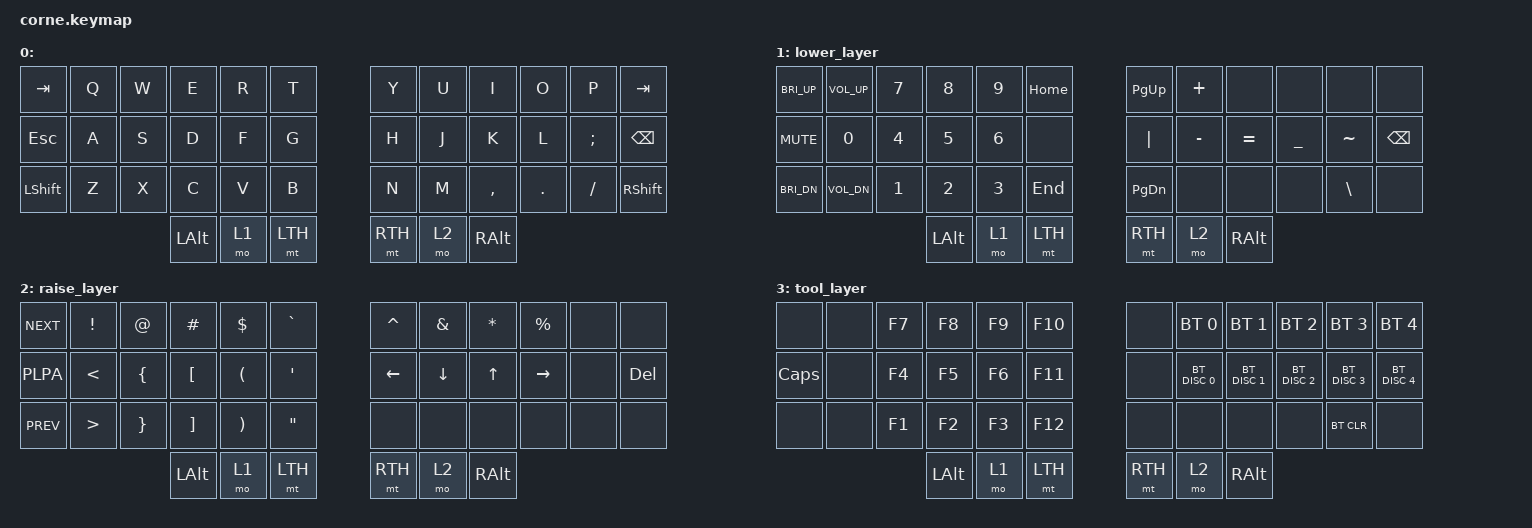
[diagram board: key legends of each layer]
#include <behaviors.dtsi>

#include <dt-bindings/zmk/bt.h>
#include <dt-bindings/zmk/keys.h>

#define LTH LCTRL SPACE
#define RTH LMETA RET

#define VOL_UP C_VOL_UP
#define VOL_DN C_VOL_DN
#define MUTE   C_MUTE

#define BRI_UP C_BRI_UP
#define BRI_DN C_BRI_DN

#define PLPA   C_PP
#define NEXT   C_NEXT
#define PREV   C_PREV

&mt {
  tapping-term-ms = <177>;
};

&caps_word {
    mods = <(MOD_LSFT | MOD_LALT)>;
};

/ {
  conditional_layers {
    compatible = "zmk,conditional-layers";

    lower_temp {
      if-layers = <1 2>;
      then-layer = <3>;
    };
  };

  keymap {
    compatible = "zmk,keymap";

    default_layer {
      label = " ";
      bindings = <
        &kp TAB    &kp Q  &kp W  &kp E  &kp R    &kp T                        &kp Y   &kp U  &kp I          &kp O    &kp P     &kp TAB
        &kp ESC    &kp A  &kp S  &kp D  &kp F    &kp G                        &kp H   &kp J  &kp K          &kp L    &kp SEMI  &kp BSPC
        &kp LSHFT  &kp Z  &kp X  &kp C  &kp V    &kp B                        &kp N   &kp M  &kp COMMA      &kp DOT  &kp FSLH  &kp RSHIFT
                                        &kp LALT &mo 1  &mt LTH      &mt RTH  &mo 2   &kp RALT
      >;
    };


    lower_layer {
      bindings = <
        &kp BRI_UP &kp VOL_UP &kp N7   &kp N8   &kp N9   &kp HOME                     &kp PG_UP  &kp PLUS   &none     &none     &none     &none
        &kp MUTE   &kp N0     &kp N4   &kp N5   &kp N6   &none                        &kp PIPE   &kp MINUS  &kp EQUAL &kp UNDER &kp TILDE &kp BSPC
        &kp BRI_DN &kp VOL_DN &kp N1   &kp N2   &kp N3   &kp END                      &kp PG_DN  &none      &none     &none     &kp BSLH  &none
                                                &kp LALT &mo 1    &mt LTH   &mt RTH   &mo 2      &kp RALT
      >;
    };

    raise_layer {
      bindings = <
        &kp NEXT  &kp EXCL  &kp AT    &kp HASH  &kp DLLR  &kp GRAVE                   &kp CARET  &kp AMPS   &kp ASTRK  &kp PRCNT  &none     &none
        &kp PLPA  &kp LT    &kp LBRC  &kp LBKT  &kp LPAR  &kp SQT                     &kp LEFT   &kp DOWN   &kp UP     &kp RIGHT  &none     &kp DEL
        &kp PREV  &kp GT    &kp RBRC  &kp RBKT  &kp RPAR  &kp DQT                     &none      &none      &none      &none      &none     &none
                                                &kp LALT  &mo 1  &mt LTH     &mt RTH  &mo 2      &kp RALT
      >;
    };


    tool_layer {
      bindings = <
        &none     &none  &kp F7   &kp F8     &kp F9   &kp F10                      &none  &bt BT_SEL  0  &bt BT_SEL  1  &bt BT_SEL  2  &bt BT_SEL  3  &bt BT_SEL  4
        &kp CAPS  &none  &kp F4   &kp F5     &kp F6   &kp F11                      &none  &bt BT_DISC 0  &bt BT_DISC 1  &bt BT_DISC 2  &bt BT_DISC 3  &bt BT_DISC 4
        &none     &none  &kp F1   &kp F2     &kp F3   &kp F12                      &none  &none          &none          &none          &bt BT_CLR     &none
                                             &kp LALT &mo 1    &mt LTH    &mt RTH  &mo 2  &kp RALT
      >;
    };
  };
};
